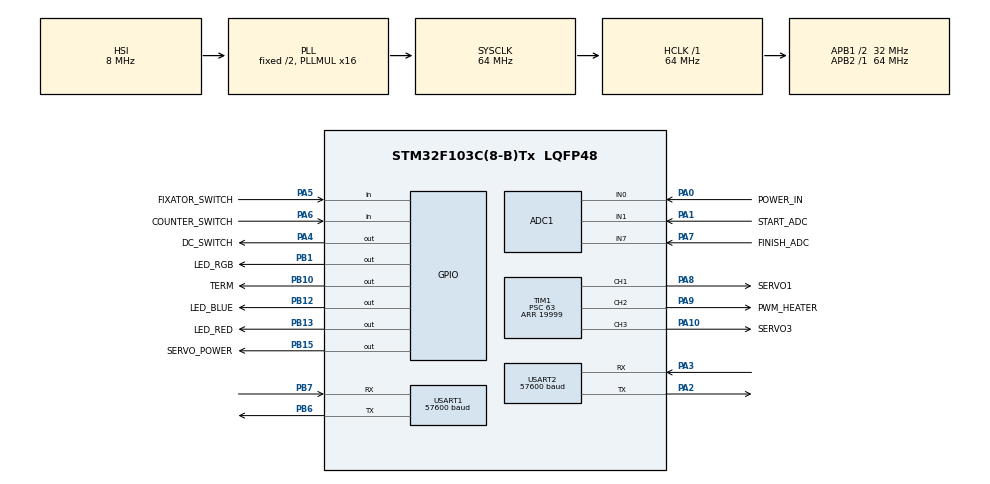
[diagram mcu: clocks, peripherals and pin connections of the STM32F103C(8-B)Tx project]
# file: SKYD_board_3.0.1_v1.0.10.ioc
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ADC1.Channel-1\#ChannelRegularConversion=ADC_CHANNEL_0
ADC1.Channel-2\#ChannelRegularConversion=ADC_CHANNEL_0
ADC1.Channel-3\#ChannelRegularConversion=ADC_CHANNEL_0
ADC1.ContinuousConvMode=ENABLE
ADC1.NbrOfConversion=3
ADC1.NbrOfConversionFlag=1
ADC1.Rank-1\#ChannelRegularConversion=1
ADC1.Rank-2\#ChannelRegularConversion=2
ADC1.Rank-3\#ChannelRegularConversion=3
ADC1.SamplingTime-1\#ChannelRegularConversion=ADC_SAMPLETIME_28CYCLES_5
ADC1.SamplingTime-2\#ChannelRegularConversion=ADC_SAMPLETIME_28CYCLES_5
ADC1.SamplingTime-3\#ChannelRegularConversion=ADC_SAMPLETIME_28CYCLES_5
ADC1.master=1
Dma.ADC1.2.Direction=DMA_PERIPH_TO_MEMORY
Dma.ADC1.2.Instance=DMA1_Channel1
Dma.ADC1.2.MemDataAlignment=DMA_MDATAALIGN_HALFWORD
Dma.ADC1.2.MemInc=DMA_MINC_ENABLE
Dma.ADC1.2.Mode=DMA_CIRCULAR
Dma.ADC1.2.PeriphDataAlignment=DMA_PDATAALIGN_HALFWORD
Dma.ADC1.2.PeriphInc=DMA_PINC_DISABLE
Dma.ADC1.2.Priority=DMA_PRIORITY_LOW
Dma.Request0=USART1_TX
Dma.Request1=USART2_TX
Dma.Request2=ADC1
Dma.USART1_TX.0.Direction=DMA_MEMORY_TO_PERIPH
Dma.USART1_TX.0.Instance=DMA1_Channel4
Dma.USART1_TX.0.MemDataAlignment=DMA_MDATAALIGN_BYTE
Dma.USART1_TX.0.MemInc=DMA_MINC_ENABLE
Dma.USART1_TX.0.Mode=DMA_NORMAL
Dma.USART1_TX.0.PeriphDataAlignment=DMA_PDATAALIGN_BYTE
Dma.USART1_TX.0.PeriphInc=DMA_PINC_DISABLE
Dma.USART1_TX.0.Priority=DMA_PRIORITY_LOW
Dma.USART2_TX.1.Direction=DMA_MEMORY_TO_PERIPH
Dma.USART2_TX.1.Instance=DMA1_Channel7
Dma.USART2_TX.1.MemDataAlignment=DMA_MDATAALIGN_BYTE
Dma.USART2_TX.1.MemInc=DMA_MINC_ENABLE
Dma.USART2_TX.1.Mode=DMA_NORMAL
Dma.USART2_TX.1.PeriphDataAlignment=DMA_PDATAALIGN_BYTE
Dma.USART2_TX.1.PeriphInc=DMA_PINC_DISABLE
Dma.USART2_TX.1.Priority=DMA_PRIORITY_LOW
Mcu.Family=STM32F1
Mcu.Name=STM32F103C(8-B)Tx
Mcu.Package=LQFP48
NVIC.DMA1_Channel1_IRQn=true\:0\:0\:false\:false\:true\:false\:true\:true
NVIC.DMA1_Channel4_IRQn=true\:0\:0\:false\:false\:true\:false\:true\:true
NVIC.DMA1_Channel7_IRQn=true\:0\:0\:false\:false\:true\:false\:true\:true
NVIC.PriorityGroup=NVIC_PRIORITYGROUP_4
NVIC.TIM2_IRQn=true\:0\:0\:false\:false\:true\:true\:true\:true
NVIC.TIM4_IRQn=true\:0\:0\:false\:false\:true\:true\:true\:true
NVIC.USART1_IRQn=true\:0\:0\:false\:false\:true\:true\:true\:true
NVIC.USART2_IRQn=true\:0\:0\:false\:false\:true\:true\:true\:true
PA0-WKUP.GPIO_Label=POWER_IN
PA0-WKUP.Signal=ADCx_IN0
PA1.GPIO_Label=START_ADC
PA1.Signal=ADCx_IN1
PA10.GPIO_Label=SERVO3
PA10.Signal=S_TIM1_CH3
PA13.Mode=Serial_Wire
PA13.Signal=SYS_JTMS-SWDIO
PA14.Mode=Serial_Wire
PA14.Signal=SYS_JTCK-SWCLK
PA2.Mode=Asynchronous
PA2.Signal=USART2_TX
PA3.Mode=Asynchronous
PA3.Signal=USART2_RX
PA4.GPIO_Label=DC_SWITCH
PA4.Signal=GPIO_Output
PA5.GPIO_Label=FIXATOR_SWITCH
PA5.Signal=GPIO_Input
PA6.GPIO_Label=COUNTER_SWITCH
PA6.Signal=GPIO_Input
PA7.GPIO_Label=FINISH_ADC
PA7.Signal=ADCx_IN7
PA8.GPIO_Label=SERVO1
PA8.Signal=S_TIM1_CH1
PA9.GPIO_Label=PWM_HEATER
PA9.GPIO_ModeDefaultPP=GPIO_MODE_AF_OD
PA9.GPIO_Speed=GPIO_SPEED_FREQ_LOW
PA9.Signal=S_TIM1_CH2
PB1.GPIO_Label=LED_RGB
PB1.Signal=GPIO_Output
PB10.GPIO_Label=TERM
PB10.GPIO_ModeDefaultOutputPP=GPIO_MODE_OUTPUT_OD
PB10.GPIO_PuPd=GPIO_NOPULL
PB10.Signal=GPIO_Output
PB12.GPIO_Label=LED_BLUE
PB12.Signal=GPIO_Output
PB13.GPIO_Label=LED_RED
PB13.Signal=GPIO_Output
PB15.GPIO_Label=SERVO_POWER
PB15.GPIO_PuPd=GPIO_PULLDOWN
PB15.Signal=GPIO_Output
PB6.Mode=Asynchronous
PB6.Signal=USART1_TX
PB7.Mode=Asynchronous
PB7.Signal=USART1_RX
ProjectManager.HeapSize=0x200
ProjectManager.StackSize=0x400
ProjectManager.TargetToolchain=STM32CubeIDE
RCC.ADCPresc=RCC_ADCPCLK2_DIV8
RCC.AHBFreq_Value=64000000
RCC.APB1CLKDivider=RCC_HCLK_DIV2
RCC.APB1Freq_Value=32000000
RCC.APB1TimFreq_Value=64000000
RCC.APB2Freq_Value=64000000
RCC.APB2TimFreq_Value=64000000
RCC.HCLKFreq_Value=64000000
RCC.PLLMUL=RCC_PLL_MUL16
RCC.SYSCLKFreq_VALUE=64000000
RCC.SYSCLKSource=RCC_SYSCLKSOURCE_PLLCLK
RCC.USBFreq_Value=64000000
SH.ADCx_IN0.0=ADC1_IN0,IN0
SH.ADCx_IN1.0=ADC1_IN1,IN1
SH.ADCx_IN7.0=ADC1_IN7,IN7
SH.S_TIM1_CH1.0=TIM1_CH1,PWM Generation1 CH1
SH.S_TIM1_CH2.0=TIM1_CH2,PWM Generation2 CH2
SH.S_TIM1_CH3.0=TIM1_CH3,PWM Generation3 CH3
TIM1.Channel-PWM\ Generation1\ CH1=TIM_CHANNEL_1
TIM1.Channel-PWM\ Generation2\ CH2=TIM_CHANNEL_2
TIM1.Channel-PWM\ Generation3\ CH3=TIM_CHANNEL_3
TIM1.OCPolarity_2=TIM_OCPOLARITY_LOW
TIM1.Period=19999
TIM1.Prescaler=63
TIM1.Pulse-PWM\ Generation2\ CH2=19999
TIM2.Period=65535
TIM2.Prescaler=63
USART1.BaudRate=57600
USART1.VirtualMode=VM_ASYNC
USART2.BaudRate=57600
USART2.VirtualMode=VM_ASYNC
VP_RTC_No_RTC_Output.Mode=RTC_OUT_NO
VP_RTC_VS_RTC_Activate.Mode=RTC_Enabled
VP_TIM1_VS_ClockSourceINT.Mode=Internal
VP_TIM2_VS_ClockSourceINT.Mode=Internal
VP_TIM4_VS_ClockSourceINT.Mode=Internal
board=custom

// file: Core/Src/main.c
/* USER CODE BEGIN Header */
/**
  ******************************************************************************
  * @file           : main.c
  * @brief          : Application entry point and main loop
  *
  * This file is intentionally thin. It owns only:
  *   1. Peripheral init (generated by CubeMX)
  *   2. app_init() — one-time startup
  *   3. The main loop — calls module tick functions in order
  *
  * Business logic lives in App/ and Drivers/ — not here.
  ******************************************************************************
  */
/* USER CODE END Header */
#include "main.h"
#include "adc.h"
#include "dma.h"
#include "rtc.h"
#include "tim.h"
#include "usart.h"
#include "gpio.h"

/* USER CODE BEGIN Includes */
#include "app.h"
#include "App/flasher.h"
/* USER CODE END Includes */

void SystemClock_Config(void);

int main(void)
{

  /* MCU Configuration--------------------------------------------------------*/

  /* Reset of all peripherals, Initializes the Flash interface and the Systick. */
  HAL_Init();

  /* Configure the system clock */
  SystemClock_Config();

  /* Initialize all configured peripherals */
  MX_GPIO_Init();
  MX_DMA_Init();
  MX_TIM1_Init();
  MX_USART2_UART_Init();
  MX_USART1_UART_Init();
  MX_TIM4_Init();
  MX_TIM2_Init();
  MX_ADC1_Init();
  MX_RTC_Init();
  /* USER CODE BEGIN 2 */

  app_init();
  /* USER CODE END 2 */

  /* Infinite loop */
  /* USER CODE BEGIN WHILE */
	  app_update();
    /* USER CODE END WHILE */

  }
}

void SystemClock_Config(void)
{
  RCC_OscInitTypeDef RCC_OscInitStruct = {0};
  RCC_ClkInitTypeDef RCC_ClkInitStruct = {0};
  RCC_PeriphCLKInitTypeDef PeriphClkInit = {0};

  /** Initializes the RCC Oscillators according to the specified parameters
  * in the RCC_OscInitTypeDef structure.
  */
  RCC_OscInitStruct.OscillatorType = RCC_OSCILLATORTYPE_HSI|RCC_OSCILLATORTYPE_LSI;
  RCC_OscInitStruct.HSIState = RCC_HSI_ON;
  RCC_OscInitStruct.HSICalibrationValue = RCC_HSICALIBRATION_DEFAULT;
  RCC_OscInitStruct.LSIState = RCC_LSI_ON;
  RCC_OscInitStruct.PLL.PLLState = RCC_PLL_ON;
  RCC_OscInitStruct.PLL.PLLSource = RCC_PLLSOURCE_HSI_DIV2;
  RCC_OscInitStruct.PLL.PLLMUL = RCC_PLL_MUL16;
  if (HAL_RCC_OscConfig(&RCC_OscInitStruct) != HAL_OK)
  {
    Error_Handler();
  }

  /** Initializes the CPU, AHB and APB buses clocks
  */
  RCC_ClkInitStruct.ClockType = RCC_CLOCKTYPE_HCLK|RCC_CLOCKTYPE_SYSCLK
                              |RCC_CLOCKTYPE_PCLK1|RCC_CLOCKTYPE_PCLK2;
  RCC_ClkInitStruct.SYSCLKSource = RCC_SYSCLKSOURCE_PLLCLK;
  RCC_ClkInitStruct.AHBCLKDivider = RCC_SYSCLK_DIV1;
  RCC_ClkInitStruct.APB1CLKDivider = RCC_HCLK_DIV2;
  RCC_ClkInitStruct.APB2CLKDivider = RCC_HCLK_DIV1;

  if (HAL_RCC_ClockConfig(&RCC_ClkInitStruct, FLASH_LATENCY_2) != HAL_OK)
  {
    Error_Handler();
  }
  PeriphClkInit.PeriphClockSelection = RCC_PERIPHCLK_RTC|RCC_PERIPHCLK_ADC;
  PeriphClkInit.RTCClockSelection = RCC_RTCCLKSOURCE_LSI;
  PeriphClkInit.AdcClockSelection = RCC_ADCPCLK2_DIV8;
  if (HAL_RCCEx_PeriphCLKConfig(&PeriphClkInit) != HAL_OK)
  {
    Error_Handler();
  }
}

void Error_Handler(void)
{
  __disable_irq();
  while (1)
  {
  }
}
